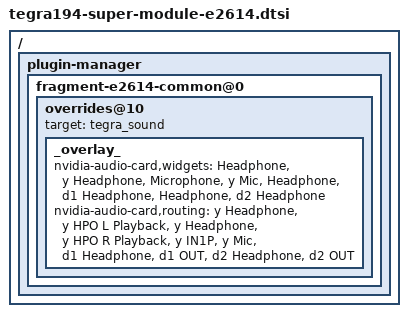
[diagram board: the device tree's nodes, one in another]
/*
 * tegra194-super-module-e2614.dtsi DTSI file.
 *
 * Copyright (c) 2019, NVIDIA CORPORATION.  All rights reserved.
 *
 * This program is free software; you can redistribute it and/or modify
 * it under the terms of the GNU General Public License as published by
 * the Free Software Foundation; version 2 of the License.
 *
 * This program is distributed in the hope that it will be useful, but WITHOUT
 * ANY WARRANTY; without even the implied warranty of MERCHANTABILITY or
 * FITNESS FOR A PARTICULAR PURPOSE.  See the GNU General Public License for
 * more details.
 */

#include <t19x-common-modules/tegra194-super-module-e2614.dtsi>

/ {
	plugin-manager {
		fragment-e2614-common@0 {
			overrides@10 {
				target = <&tegra_sound>;
				_overlay_ {
					nvidia-audio-card,widgets =
						"Headphone",	"y Headphone",
						"Microphone",	"y Mic",
						"Headphone",	"d1 Headphone",
						"Headphone",	"d2 Headphone";

					nvidia-audio-card,routing =
						"y Headphone",          "y HPO L Playback",
						"y Headphone",          "y HPO R Playback",
						"y IN1P",               "y Mic",
						"d1 Headphone",         "d1 OUT",
						"d2 Headphone",         "d2 OUT";
				};
			};
		};
	};
};
